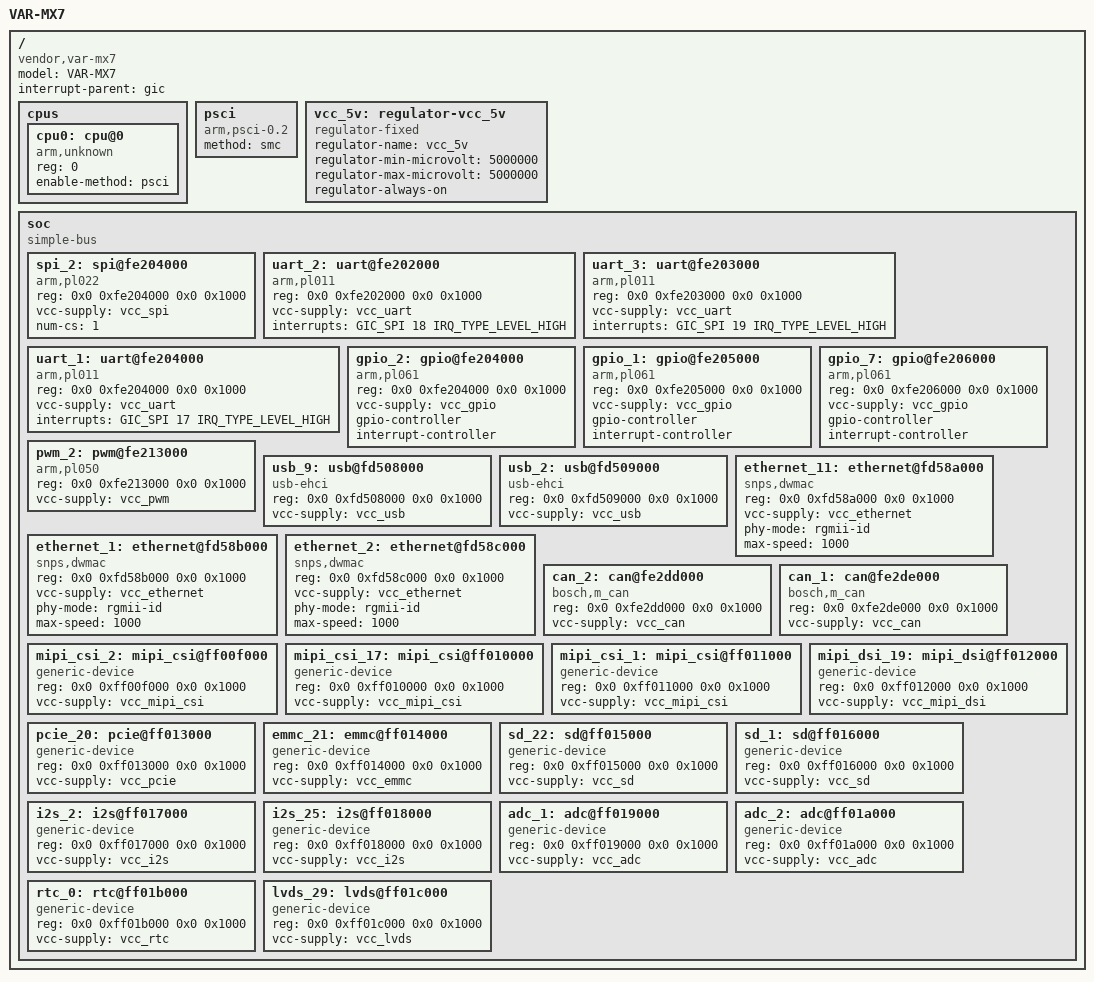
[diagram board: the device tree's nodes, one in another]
/dts-v1/;

/* Generated by @dt_architect — PDF-to-Gadget Pipeline
 * Board: VAR-MX7
 * SoC  : Unknown SoC
 * Arch : arm64 (Unknown)
 * Date : auto-generated
 */

#include <dt-bindings/interrupt-controller/arm-gic.h>
#include <dt-bindings/gpio/gpio.h>

/ {
	compatible = "vendor,var-mx7", "vendor,unknown-soc";
	model = "VAR-MX7";
	#address-cells = <2>;
	#size-cells = <2>;
	interrupt-parent = <&gic>;

	cpus {
		#address-cells = <1>;
		#size-cells = <0>;

		cpu0: cpu@0 {
			device_type = "cpu";
			compatible = "arm,unknown";
			reg = <0>;
			enable-method = "psci";
		};
	};

	psci {
		compatible = "arm,psci-0.2";
		method = "smc";
	};

	/* ── Power Regulators ─────────────────────────────── */
	vcc_5v: regulator-vcc_5v {
		compatible = "regulator-fixed";
		regulator-name = "vcc_5v";
		regulator-min-microvolt = <5000000>;
		regulator-max-microvolt = <5000000>;
		regulator-always-on;
	};

	/* ── Simple Bus ──────────────────────────────────── */
	soc: soc {
		compatible = "simple-bus";
		#address-cells = <2>;
		#size-cells = <2>;
		ranges;

		spi_2: spi@fe204000 {
			compatible = "arm,pl022";
			reg = <0x0 0xfe204000 0x0 0x1000>;
			#address-cells = <1>;
			#size-cells = <0>;
			status = "okay";
			vcc-supply = <&vcc_spi>;
			/* SPI peripheral on SPI2 */
			#address-cells = <1>;
			#size-cells = <0>;
			clock-names = "spiclk", "apb_pclk";
			num-cs = <1>;
		};

		uart_2: uart@fe202000 {
			compatible = "arm,pl011";
			reg = <0x0 0xfe202000 0x0 0x1000>;
			#address-cells = <1>;
			#size-cells = <0>;
			status = "okay";
			vcc-supply = <&vcc_uart>;
			/* UART peripheral on UART2 */
			clock-names = "uartclk", "apb_pclk";
			interrupts = <GIC_SPI 18 IRQ_TYPE_LEVEL_HIGH>;
		};

		uart_3: uart@fe203000 {
			compatible = "arm,pl011";
			reg = <0x0 0xfe203000 0x0 0x1000>;
			#address-cells = <1>;
			#size-cells = <0>;
			status = "okay";
			vcc-supply = <&vcc_uart>;
			/* UART peripheral on UART3 */
			clock-names = "uartclk", "apb_pclk";
			interrupts = <GIC_SPI 19 IRQ_TYPE_LEVEL_HIGH>;
		};

		uart_1: uart@fe204000 {
			compatible = "arm,pl011";
			reg = <0x0 0xfe204000 0x0 0x1000>;
			#address-cells = <1>;
			#size-cells = <0>;
			status = "okay";
			vcc-supply = <&vcc_uart>;
			/* UART peripheral on UART1 */
			clock-names = "uartclk", "apb_pclk";
			interrupts = <GIC_SPI 17 IRQ_TYPE_LEVEL_HIGH>;
		};

		gpio_2: gpio@fe204000 {
			compatible = "arm,pl061";
			reg = <0x0 0xfe204000 0x0 0x1000>;
			#address-cells = <1>;
			#size-cells = <0>;
			status = "okay";
			vcc-supply = <&vcc_gpio>;
			/* GPIO peripheral on GPIO2 */
			gpio-controller;
			#gpio-cells = <2>;
			interrupt-controller;
			#interrupt-cells = <2>;
		};

		gpio_1: gpio@fe205000 {
			compatible = "arm,pl061";
			reg = <0x0 0xfe205000 0x0 0x1000>;
			#address-cells = <1>;
			#size-cells = <0>;
			status = "okay";
			vcc-supply = <&vcc_gpio>;
			/* GPIO peripheral on GPIO1 */
			gpio-controller;
			#gpio-cells = <2>;
			interrupt-controller;
			#interrupt-cells = <2>;
		};

		gpio_7: gpio@fe206000 {
			compatible = "arm,pl061";
			reg = <0x0 0xfe206000 0x0 0x1000>;
			#address-cells = <1>;
			#size-cells = <0>;
			status = "okay";
			vcc-supply = <&vcc_gpio>;
			/* GPIO peripheral on GPIO7 */
			gpio-controller;
			#gpio-cells = <2>;
			interrupt-controller;
			#interrupt-cells = <2>;
		};

		pwm_2: pwm@fe213000 {
			compatible = "arm,pl050";
			reg = <0x0 0xfe213000 0x0 0x1000>;
			#address-cells = <1>;
			#size-cells = <0>;
			status = "okay";
			vcc-supply = <&vcc_pwm>;
			/* PWM peripheral on PWM2 */
		};

		usb_9: usb@fd508000 {
			compatible = "usb-ehci";
			reg = <0x0 0xfd508000 0x0 0x1000>;
			#address-cells = <1>;
			#size-cells = <0>;
			status = "okay";
			vcc-supply = <&vcc_usb>;
			/* USB peripheral on USB */
		};

		usb_2: usb@fd509000 {
			compatible = "usb-ehci";
			reg = <0x0 0xfd509000 0x0 0x1000>;
			#address-cells = <1>;
			#size-cells = <0>;
			status = "okay";
			vcc-supply = <&vcc_usb>;
			/* USB peripheral on USB2 */
		};

		ethernet_11: ethernet@fd58a000 {
			compatible = "snps,dwmac";
			reg = <0x0 0xfd58a000 0x0 0x1000>;
			#address-cells = <1>;
			#size-cells = <0>;
			status = "okay";
			vcc-supply = <&vcc_ethernet>;
			/* ETHERNET peripheral on ETHERNET */
			clock-names = "stmmaceth", "pclk", "ptp_ref";
			phy-mode = "rgmii-id";
			max-speed = <1000>;
		};

		ethernet_1: ethernet@fd58b000 {
			compatible = "snps,dwmac";
			reg = <0x0 0xfd58b000 0x0 0x1000>;
			#address-cells = <1>;
			#size-cells = <0>;
			status = "okay";
			vcc-supply = <&vcc_ethernet>;
			/* ETHERNET peripheral on ETHERNET1 */
			clock-names = "stmmaceth", "pclk", "ptp_ref";
			phy-mode = "rgmii-id";
			max-speed = <1000>;
		};

		ethernet_2: ethernet@fd58c000 {
			compatible = "snps,dwmac";
			reg = <0x0 0xfd58c000 0x0 0x1000>;
			#address-cells = <1>;
			#size-cells = <0>;
			status = "okay";
			vcc-supply = <&vcc_ethernet>;
			/* ETHERNET peripheral on ETHERNET2 */
			clock-names = "stmmaceth", "pclk", "ptp_ref";
			phy-mode = "rgmii-id";
			max-speed = <1000>;
		};

		can_2: can@fe2dd000 {
			compatible = "bosch,m_can";
			reg = <0x0 0xfe2dd000 0x0 0x1000>;
			#address-cells = <1>;
			#size-cells = <0>;
			status = "okay";
			vcc-supply = <&vcc_can>;
			/* CAN peripheral on CAN2 */
		};

		can_1: can@fe2de000 {
			compatible = "bosch,m_can";
			reg = <0x0 0xfe2de000 0x0 0x1000>;
			#address-cells = <1>;
			#size-cells = <0>;
			status = "okay";
			vcc-supply = <&vcc_can>;
			/* CAN peripheral on CAN1 */
		};

		mipi_csi_2: mipi_csi@ff00f000 {
			compatible = "generic-device";
			reg = <0x0 0xff00f000 0x0 0x1000>;
			#address-cells = <1>;
			#size-cells = <0>;
			status = "okay";
			vcc-supply = <&vcc_mipi_csi>;
			/* MIPI_CSI peripheral on MIPI_CSI2 */
		};

		mipi_csi_17: mipi_csi@ff010000 {
			compatible = "generic-device";
			reg = <0x0 0xff010000 0x0 0x1000>;
			#address-cells = <1>;
			#size-cells = <0>;
			status = "okay";
			vcc-supply = <&vcc_mipi_csi>;
			/* MIPI_CSI peripheral on MIPI_CSI */
		};

		mipi_csi_1: mipi_csi@ff011000 {
			compatible = "generic-device";
			reg = <0x0 0xff011000 0x0 0x1000>;
			#address-cells = <1>;
			#size-cells = <0>;
			status = "okay";
			vcc-supply = <&vcc_mipi_csi>;
			/* MIPI_CSI peripheral on MIPI_CSI1 */
		};

		mipi_dsi_19: mipi_dsi@ff012000 {
			compatible = "generic-device";
			reg = <0x0 0xff012000 0x0 0x1000>;
			#address-cells = <1>;
			#size-cells = <0>;
			status = "okay";
			vcc-supply = <&vcc_mipi_dsi>;
			/* MIPI_DSI peripheral on MIPI_DSI */
		};

		pcie_20: pcie@ff013000 {
			compatible = "generic-device";
			reg = <0x0 0xff013000 0x0 0x1000>;
			#address-cells = <1>;
			#size-cells = <0>;
			status = "okay";
			vcc-supply = <&vcc_pcie>;
			/* PCIE peripheral on PCIE */
		};

		emmc_21: emmc@ff014000 {
			compatible = "generic-device";
			reg = <0x0 0xff014000 0x0 0x1000>;
			#address-cells = <1>;
			#size-cells = <0>;
			status = "okay";
			vcc-supply = <&vcc_emmc>;
			/* EMMC peripheral on EMMC */
		};

		sd_22: sd@ff015000 {
			compatible = "generic-device";
			reg = <0x0 0xff015000 0x0 0x1000>;
			#address-cells = <1>;
			#size-cells = <0>;
			status = "okay";
			vcc-supply = <&vcc_sd>;
			/* SD peripheral on SD */
		};

		sd_1: sd@ff016000 {
			compatible = "generic-device";
			reg = <0x0 0xff016000 0x0 0x1000>;
			#address-cells = <1>;
			#size-cells = <0>;
			status = "okay";
			vcc-supply = <&vcc_sd>;
			/* SD peripheral on SD1 */
		};

		i2s_2: i2s@ff017000 {
			compatible = "generic-device";
			reg = <0x0 0xff017000 0x0 0x1000>;
			#address-cells = <1>;
			#size-cells = <0>;
			status = "okay";
			vcc-supply = <&vcc_i2s>;
			/* I2S peripheral on I2S2 */
		};

		i2s_25: i2s@ff018000 {
			compatible = "generic-device";
			reg = <0x0 0xff018000 0x0 0x1000>;
			#address-cells = <1>;
			#size-cells = <0>;
			status = "okay";
			vcc-supply = <&vcc_i2s>;
			/* I2S peripheral on I2S */
		};

		adc_1: adc@ff019000 {
			compatible = "generic-device";
			reg = <0x0 0xff019000 0x0 0x1000>;
			#address-cells = <1>;
			#size-cells = <0>;
			status = "okay";
			vcc-supply = <&vcc_adc>;
			/* ADC peripheral on ADC1 */
		};

		adc_2: adc@ff01a000 {
			compatible = "generic-device";
			reg = <0x0 0xff01a000 0x0 0x1000>;
			#address-cells = <1>;
			#size-cells = <0>;
			status = "okay";
			vcc-supply = <&vcc_adc>;
			/* ADC peripheral on ADC2 */
		};

		rtc_0: rtc@ff01b000 {
			compatible = "generic-device";
			reg = <0x0 0xff01b000 0x0 0x1000>;
			#address-cells = <1>;
			#size-cells = <0>;
			status = "okay";
			vcc-supply = <&vcc_rtc>;
			/* RTC peripheral on RTC0 */
		};

		lvds_29: lvds@ff01c000 {
			compatible = "generic-device";
			reg = <0x0 0xff01c000 0x0 0x1000>;
			#address-cells = <1>;
			#size-cells = <0>;
			status = "okay";
			vcc-supply = <&vcc_lvds>;
			/* LVDS peripheral on LVDS */
		};
	};
};
